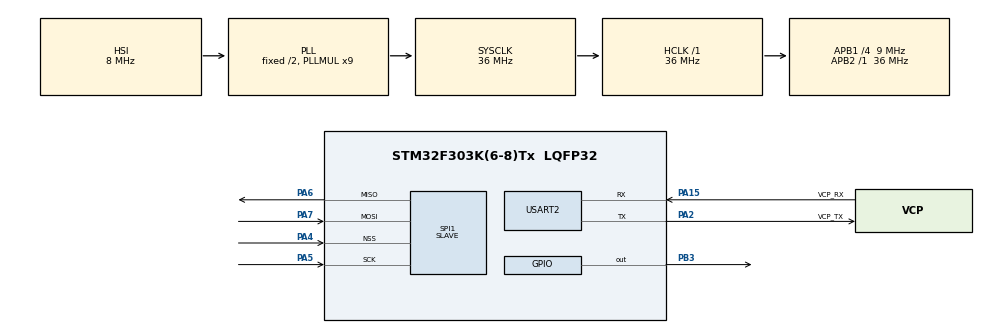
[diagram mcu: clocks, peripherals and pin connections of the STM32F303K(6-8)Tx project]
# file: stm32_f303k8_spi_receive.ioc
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Dma.Request0=SPI1_RX
Dma.Request1=SPI1_TX
Dma.SPI1_RX.0.Direction=DMA_PERIPH_TO_MEMORY
Dma.SPI1_RX.0.Instance=DMA1_Channel2
Dma.SPI1_RX.0.MemDataAlignment=DMA_MDATAALIGN_BYTE
Dma.SPI1_RX.0.MemInc=DMA_MINC_ENABLE
Dma.SPI1_RX.0.Mode=DMA_NORMAL
Dma.SPI1_RX.0.PeriphDataAlignment=DMA_PDATAALIGN_BYTE
Dma.SPI1_RX.0.PeriphInc=DMA_PINC_DISABLE
Dma.SPI1_RX.0.Priority=DMA_PRIORITY_LOW
Dma.SPI1_TX.1.Direction=DMA_MEMORY_TO_PERIPH
Dma.SPI1_TX.1.Instance=DMA1_Channel3
Dma.SPI1_TX.1.MemDataAlignment=DMA_MDATAALIGN_BYTE
Dma.SPI1_TX.1.MemInc=DMA_MINC_ENABLE
Dma.SPI1_TX.1.Mode=DMA_NORMAL
Dma.SPI1_TX.1.PeriphDataAlignment=DMA_PDATAALIGN_BYTE
Dma.SPI1_TX.1.PeriphInc=DMA_PINC_DISABLE
Dma.SPI1_TX.1.Priority=DMA_PRIORITY_LOW
Mcu.Family=STM32F3
Mcu.Name=STM32F303K(6-8)Tx
Mcu.Package=LQFP32
NVIC.DMA1_Channel2_IRQn=true\:0\:0\:false\:false\:true\:false\:true
NVIC.DMA1_Channel3_IRQn=true\:0\:0\:false\:false\:true\:false\:true
NVIC.PriorityGroup=NVIC_PRIORITYGROUP_4
PA13.GPIO_Label=SWDIO
PA13.Mode=Serial_Wire
PA13.Signal=SYS_JTMS-SWDIO
PA14.GPIO_Label=SWCLK
PA14.Mode=Serial_Wire
PA14.Signal=SYS_JTCK-SWCLK
PA15.GPIO_Label=VCP_RX
PA15.Mode=Asynchronous
PA15.Signal=USART2_RX
PA2.GPIO_Label=VCP_TX
PA2.Mode=Asynchronous
PA2.Signal=USART2_TX
PA4.GPIO_PuPd=GPIO_NOPULL
PA4.Mode=NSS_Signal_Hard_Input
PA4.Signal=SPI1_NSS
PA5.GPIO_PuPd=GPIO_PULLUP
PA5.Mode=Full_Duplex_Slave
PA5.Signal=SPI1_SCK
PA6.GPIO_PuPd=GPIO_PULLUP
PA6.Mode=Full_Duplex_Slave
PA6.Signal=SPI1_MISO
PA7.GPIO_PuPd=GPIO_PULLUP
PA7.Mode=Full_Duplex_Slave
PA7.Signal=SPI1_MOSI
PB3.Signal=GPIO_Output
PF0\ /\ OSC_IN.GPIO_Label=MCO
PF0\ /\ OSC_IN.Mode=HSE-External-Clock-Source
PF0\ /\ OSC_IN.Signal=RCC_OSC_IN
ProjectManager.HeapSize=0x200
ProjectManager.StackSize=0x400
ProjectManager.TargetToolchain=STM32CubeIDE
RCC.AHBFreq_Value=36000000
RCC.APB1CLKDivider=RCC_HCLK_DIV4
RCC.APB1Freq_Value=9000000
RCC.APB1TimFreq_Value=18000000
RCC.APB2Freq_Value=36000000
RCC.APB2TimFreq_Value=36000000
RCC.CortexFreq_Value=36000000
RCC.HCLKFreq_Value=36000000
RCC.HSE_VALUE=8000000
RCC.HSI_VALUE=8000000
RCC.PLLMUL=RCC_PLL_MUL9
RCC.SYSCLKFreq_VALUE=36000000
RCC.SYSCLKSourceVirtual=RCC_SYSCLKSOURCE_PLLCLK
SPI1.CLKPhase=SPI_PHASE_2EDGE
SPI1.CRCCalculation=SPI_CRCCALCULATION_DISABLE
SPI1.DataSize=SPI_DATASIZE_8BIT
SPI1.Direction=SPI_DIRECTION_2LINES
SPI1.Mode=SPI_MODE_SLAVE
SPI1.VirtualNSS=VM_NSSHARD
SPI1.VirtualType=VM_SLAVE
USART2.VirtualMode-Asynchronous=VM_ASYNC
board=NUCLEO-F303K8

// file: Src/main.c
/* USER CODE BEGIN Header */
/**
  ******************************************************************************
  * @file           : main.c
  * @brief          : Main program body
  ******************************************************************************
  * @attention
  *
  * <h2><center>&copy; Copyright (c) 2019 STMicroelectronics.
  * All rights reserved.</center></h2>
  *
  * This software component is licensed by ST under BSD 3-Clause license,
  * the "License"; You may not use this file except in compliance with the
  * License. You may obtain a copy of the License at:
  *                        opensource.org/licenses/BSD-3-Clause
  *
  ******************************************************************************
  */
/* USER CODE END Header */

#include "main.h"

SPI_HandleTypeDef hspi1;
DMA_HandleTypeDef hdma_spi1_rx;
DMA_HandleTypeDef hdma_spi1_tx;

UART_HandleTypeDef huart2;

void SystemClock_Config(void);
static void MX_GPIO_Init(void);
static void MX_DMA_Init(void);
static void MX_SPI1_Init(void);
static void MX_USART2_UART_Init(void);

int main(void)
{
  /* USER CODE BEGIN 1 */
	uint8_t aTxBuffer1[]={'A','B','C','D','E','F'};
	uint8_t aTxBuffer2[11]={0};
	uint8_t aRxBuffer1[6]={0};
	uint8_t aRxBuffer2[11]={0};
	uint8_t flag = 0;
  /* USER CODE END 1 */

  /* MCU Configuration--------------------------------------------------------*/

  /* Reset of all peripherals, Initializes the Flash interface and the Systick. */
  HAL_Init();

  /* Configure the system clock */
  SystemClock_Config();

  /* Initialize all configured peripherals */
  MX_GPIO_Init();
  MX_DMA_Init();
  MX_SPI1_Init();
  MX_USART2_UART_Init();
  /* USER CODE BEGIN 2 */
  //HAL_SPI_TransmitReceive_IT(&hspi1,(uint8_t*)aTxBuffer1,(uint8_t*)aRxBuffer1,11);
  /* USER CODE END 2 */

  /* Infinite loop */
  while (1)
  {

    /* USER CODE BEGIN 3 */
	  HAL_SPI_TransmitReceive_DMA(&hspi1, aTxBuffer1, aRxBuffer1, 6);
	  //何かの処理
	 // for(int i=0; i < 6; i++){
	//	  HAL_SPI_TransmitReceive(&hspi1,(uint8_t*)&aTxBuffer1[i],(uint8_t*)&aRxBuffer1[i],1,0xFFFFFFFF);
	//	  HAL_Delay(1);
	  //}
	  HAL_Delay(1);

  }
  /* USER CODE END 3 */
}

void SystemClock_Config(void)
{
  RCC_OscInitTypeDef RCC_OscInitStruct = {0};
  RCC_ClkInitTypeDef RCC_ClkInitStruct = {0};

  /** Initializes the CPU, AHB and APB busses clocks
  */
  RCC_OscInitStruct.OscillatorType = RCC_OSCILLATORTYPE_HSI;
  RCC_OscInitStruct.HSIState = RCC_HSI_ON;
  RCC_OscInitStruct.HSICalibrationValue = RCC_HSICALIBRATION_DEFAULT;
  RCC_OscInitStruct.PLL.PLLState = RCC_PLL_ON;
  RCC_OscInitStruct.PLL.PLLSource = RCC_PLLSOURCE_HSI;
  RCC_OscInitStruct.PLL.PLLMUL = RCC_PLL_MUL9;
  if (HAL_RCC_OscConfig(&RCC_OscInitStruct) != HAL_OK)
  {
    Error_Handler();
  }
  /** Initializes the CPU, AHB and APB busses clocks
  */
  RCC_ClkInitStruct.ClockType = RCC_CLOCKTYPE_HCLK|RCC_CLOCKTYPE_SYSCLK
                              |RCC_CLOCKTYPE_PCLK1|RCC_CLOCKTYPE_PCLK2;
  RCC_ClkInitStruct.SYSCLKSource = RCC_SYSCLKSOURCE_PLLCLK;
  RCC_ClkInitStruct.AHBCLKDivider = RCC_SYSCLK_DIV1;
  RCC_ClkInitStruct.APB1CLKDivider = RCC_HCLK_DIV4;
  RCC_ClkInitStruct.APB2CLKDivider = RCC_HCLK_DIV1;

  if (HAL_RCC_ClockConfig(&RCC_ClkInitStruct, FLASH_LATENCY_1) != HAL_OK)
  {
    Error_Handler();
  }
}

static void MX_SPI1_Init(void)
{

  /* SPI1 parameter configuration*/
  hspi1.Instance = SPI1;
  hspi1.Init.Mode = SPI_MODE_SLAVE;
  hspi1.Init.Direction = SPI_DIRECTION_2LINES;
  hspi1.Init.DataSize = SPI_DATASIZE_8BIT;
  hspi1.Init.CLKPolarity = SPI_POLARITY_LOW;
  hspi1.Init.CLKPhase = SPI_PHASE_2EDGE;
  hspi1.Init.NSS = SPI_NSS_HARD_INPUT;
  hspi1.Init.FirstBit = SPI_FIRSTBIT_MSB;
  hspi1.Init.TIMode = SPI_TIMODE_DISABLE;
  hspi1.Init.CRCCalculation = SPI_CRCCALCULATION_DISABLE;
  hspi1.Init.CRCPolynomial = 7;
  hspi1.Init.CRCLength = SPI_CRC_LENGTH_DATASIZE;
  hspi1.Init.NSSPMode = SPI_NSS_PULSE_DISABLE;
  if (HAL_SPI_Init(&hspi1) != HAL_OK)
  {
    Error_Handler();
  }

}

static void MX_USART2_UART_Init(void)
{

  huart2.Instance = USART2;
  huart2.Init.BaudRate = 38400;
  huart2.Init.WordLength = UART_WORDLENGTH_8B;
  huart2.Init.StopBits = UART_STOPBITS_1;
  huart2.Init.Parity = UART_PARITY_NONE;
  huart2.Init.Mode = UART_MODE_TX_RX;
  huart2.Init.HwFlowCtl = UART_HWCONTROL_NONE;
  huart2.Init.OverSampling = UART_OVERSAMPLING_16;
  huart2.Init.OneBitSampling = UART_ONE_BIT_SAMPLE_DISABLE;
  huart2.AdvancedInit.AdvFeatureInit = UART_ADVFEATURE_NO_INIT;
  if (HAL_UART_Init(&huart2) != HAL_OK)
  {
    Error_Handler();
  }

}

static void MX_DMA_Init(void)
{

  /* DMA controller clock enable */
  __HAL_RCC_DMA1_CLK_ENABLE();

  /* DMA interrupt init */
  /* DMA1_Channel2_IRQn interrupt configuration */
  HAL_NVIC_SetPriority(DMA1_Channel2_IRQn, 0, 0);
  HAL_NVIC_EnableIRQ(DMA1_Channel2_IRQn);
  /* DMA1_Channel3_IRQn interrupt configuration */
  HAL_NVIC_SetPriority(DMA1_Channel3_IRQn, 0, 0);
  HAL_NVIC_EnableIRQ(DMA1_Channel3_IRQn);

}

static void MX_GPIO_Init(void)
{
  GPIO_InitTypeDef GPIO_InitStruct = {0};

  /* GPIO Ports Clock Enable */
  __HAL_RCC_GPIOF_CLK_ENABLE();
  __HAL_RCC_GPIOA_CLK_ENABLE();
  __HAL_RCC_GPIOB_CLK_ENABLE();

  /*Configure GPIO pin Output Level */
  HAL_GPIO_WritePin(GPIOB, GPIO_PIN_3, GPIO_PIN_RESET);

  /*Configure GPIO pin : PB3 */
  GPIO_InitStruct.Pin = GPIO_PIN_3;
  GPIO_InitStruct.Mode = GPIO_MODE_OUTPUT_PP;
  GPIO_InitStruct.Pull = GPIO_NOPULL;
  GPIO_InitStruct.Speed = GPIO_SPEED_FREQ_LOW;
  HAL_GPIO_Init(GPIOB, &GPIO_InitStruct);

}

/* USER CODE BEGIN 4 */
/*
void HAL_SPI_TxRxCpltCallback(SPI_HandleTypeDef *hspi){
	HAL_SPI_TransmitReceive_IT(&hspi1,(uint8_t*)aTxBuffer1,(uint8_t*)aRxBuffer1,11);
	for(int i=0; i < 100; i++){
		asm("NOP");
	}
}
*/
/* USER CODE END 4 */

void Error_Handler(void)
{
}

/************************ (C) COPYRIGHT STMicroelectronics *****END OF FILE****/
